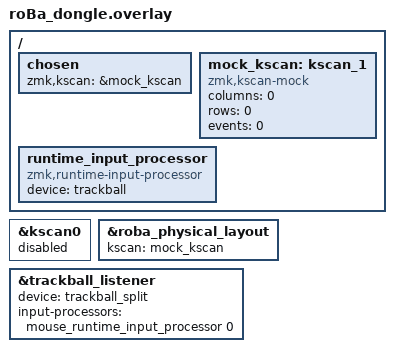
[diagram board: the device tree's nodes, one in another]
#include "roBa.dtsi"
#include <input/processors.dtsi>
#include <input/processors/runtime-input-processor.dtsi>
#include <behaviors/battery_history_request.dtsi>

&kscan0 {
	status = "disabled";
};

/ {
   chosen {
      zmk,kscan = &mock_kscan;
   };

   mock_kscan: kscan_1 {
      compatible = "zmk,kscan-mock";
      columns = <0>;
      rows = <0>;
      events = <0>;
   };
};

&roba_physical_layout {
    kscan = <&mock_kscan>;
};

/ {
    runtime_input_processor: runtime_input_processor {
        compatible = "zmk,runtime-input-processor";
        #input-processor-cells = <1>;
        device = <&trackball>; 
    };
};

&trackball_listener {
    status = "okay";
    device = <&trackball_split>;
    input-processors = <&mouse_runtime_input_processor 0>;
};
